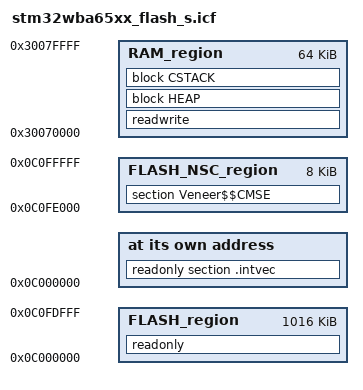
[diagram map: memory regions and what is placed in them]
/**********************************************************************************/
//*###ICF### Section handled by ICF editor, don't touch! ****/
/*-Editor annotation file-*/
/* IcfEditorFile="$TOOLKIT_DIR$\config\ide\IcfEditor\cortex_v1_0.xml" *//*-Specials-*/

/**********************************************************************************/

/*-Sizes-*/
define symbol __ICFEDIT_intvec_start__ = 0x0c000000;
define symbol __ICFEDIT_size_cstack__ = 0x1000;
define symbol __ICFEDIT_size_heap__   = 0x0000;

/*-Start of  symbols-Auto-generated By STM32CubeMX*/
/*-End of MX Symbols*/

/*-Symbols-*/
define symbol __ICFEDIT_region_RAM_start__       = 0x30070000;
define symbol __ICFEDIT_region_RAM_end__         = 0x3007FFFF;
define symbol __ICFEDIT_region_ROM_start__     = 0x0c000000;
define symbol __ICFEDIT_region_ROM_end__       = 0xC0FDFFF;
define symbol __ICFEDIT_region_ROM_NSC_start__ = 0x0c0fe000;
define symbol __ICFEDIT_region_ROM_NSC_end__   = 0xC0FFFFF;
/**** End of ICF editor section. ###ICF###*/

define memory mem with size = 4G;

/*-MEMORY Regions-*/
define region RAM_region   = mem:[from __ICFEDIT_region_RAM_start__   to __ICFEDIT_region_RAM_end__];
define region FLASH_region = mem:[from __ICFEDIT_region_ROM_start__ to __ICFEDIT_region_ROM_end__];
define region FLASH_NSC_region = mem:[from __ICFEDIT_region_ROM_NSC_start__ to __ICFEDIT_region_ROM_NSC_end__];

/*-Start of  Regions- Auto-generated By STM32CubeMX*/
/*-End of MX Regions-*/

/*-Blocks-*/
define block CSTACK with alignment = 8, size = __ICFEDIT_size_cstack__ {};
define block HEAP   with alignment = 8, size = __ICFEDIT_size_heap__  {};

/*-Initialization strategies-*/
initialize by copy { readwrite };
do not initialize  { section .noinit };

/*-Sections placements-*/
place at address mem:__ICFEDIT_intvec_start__ { readonly section .intvec };

/*-Start of  Sections- Auto-generated By STM32CubeMX*/
/*-end of MX Sections-*/

/*-user Sections-*/
place in FLASH_region  { readonly };
place in RAM_region  { readwrite, block HEAP, block CSTACK };
place in FLASH_NSC_region  { section Veneer$$CMSE };
